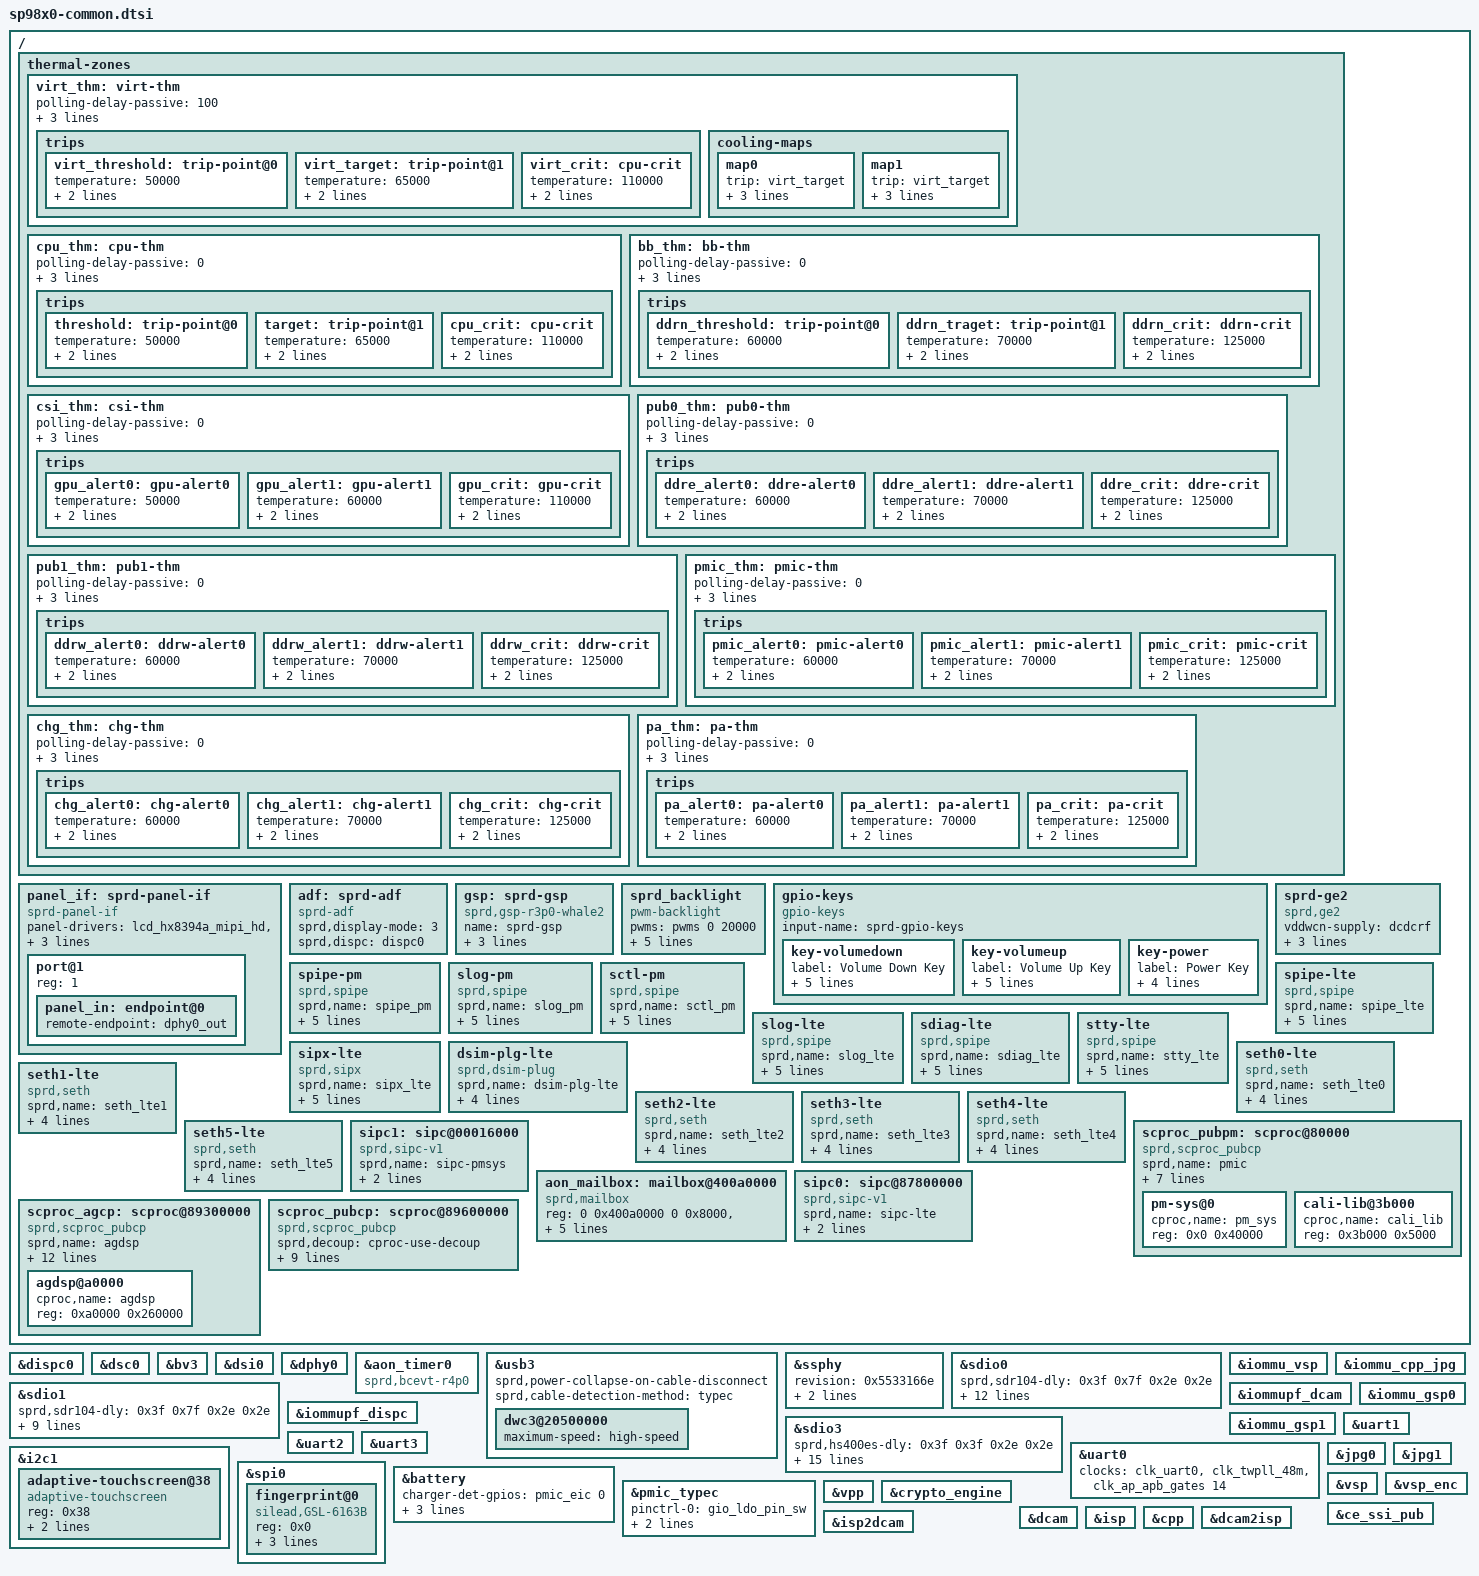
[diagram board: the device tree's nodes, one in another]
/*
 * Spreadtrum SP98x0 board common DTS file
 *
 * Copyright (C) 2016, Spreadtrum Communications Inc.
 *
 * This file is licensed under a dual GPLv2 or X11 license.
 */

#include "lcd/lcd_hx8394a_mipi_hd.dtsi"
#include "lcd/lcd_s6e3fa3_mipi_fhd.dtsi"
#include "lcd/lcd_nt35596_mipi_fhd.dtsi"
#include "lcd/lcd_nt35597_mipi_2k.dtsi"
#include "lcd/lcd_ili9885_mipi_fhd.dtsi"
#include "lcd/lcd_nt35532_mipi.dtsi"
#include "lcd/lcd_dummy_mipi.dtsi"
#include <dt-bindings/thermal/thermal.h>

/ {
	thermal-zones {

		virt_thm: virt-thm {
			polling-delay-passive = <100>;
			polling-delay = <1000>;
			sustainable-power = <2000>;

			thermal-sensors = <&virt_sensor  11>;
			trips {
				virt_threshold: trip-point@0 {
					temperature = <50000>;
					hysteresis = <1000>;
					type = "passive";
				};
				virt_target: trip-point@1 {
					temperature = <65000>;
					hysteresis = <1000>;
					type = "passive";
				};
				virt_crit: cpu-crit {
					temperature = <110000>; /* millicelsius */
					hysteresis = <2000>; /* millicelsius */
					type = "critical";
				};
			};

			cooling-maps {
				map0 {
					trip = <&virt_target>;
					contribution = <1024>;
					cooling-device =
					<&lit_cpu_cooling  THERMAL_NO_LIMIT  THERMAL_NO_LIMIT>;
				};
				map1 {
					trip = <&virt_target>;
					contribution = <761>;
					cooling-device =
					<&big_cpu_cooling  THERMAL_NO_LIMIT  THERMAL_NO_LIMIT>;
				};
			};
		};

		cpu_thm: cpu-thm {
			polling-delay-passive = <0>;
			polling-delay = <0>;
			sustainable-power = <2000>;

			thermal-sensors = <&ap_thm  0>;
			trips {
				threshold: trip-point@0 {
					temperature = <50000>;
					hysteresis = <1000>;
					type = "passive";
				};
				target: trip-point@1 {
					temperature = <65000>;
					hysteresis = <1000>;
					type = "passive";
				};
				cpu_crit: cpu-crit {
					temperature = <110000>; /* millicelsius */
					hysteresis = <2000>; /* millicelsius */
					type = "critical";
				};
			};
		};

		bb_thm: bb-thm {
			polling-delay-passive = <0>;
			polling-delay = <0>;
			sustainable-power = <2000>;
			thermal-sensors = <&ap_thm  2>;
			trips {
				ddrn_threshold: trip-point@0 {
					temperature = <60000>;
					hysteresis = <1000>;
					type = "passive";
				};
				ddrn_traget: trip-point@1 {
					temperature = <70000>;
					hysteresis = <1000>;
					type = "passive";
				};
				ddrn_crit: ddrn-crit {
					temperature = <125000>;
					hysteresis = <2000>;
					type = "critical";
				};
			};
		};

		csi_thm: csi-thm {
			polling-delay-passive = <0>;
			polling-delay = <0>;
			sustainable-power = <2000>;
			thermal-sensors = <&ap_thm  3>;
			trips {
				gpu_alert0: gpu-alert0 {
					temperature = <50000>;
					hysteresis = <1000>;
					type = "passive";
				};
				gpu_alert1: gpu-alert1 {
					temperature = <60000>;
					hysteresis = <1000>;
					type = "passive";
				};
				gpu_crit: gpu-crit {
					temperature = <110000>;
					hysteresis = <2000>;
					type = "critical";
				};
			};
		};

		pub0_thm: pub0-thm {
			polling-delay-passive = <0>;
			polling-delay = <0>;
			sustainable-power = <2000>;
			thermal-sensors = <&ap_thm  4>;
			trips {
				ddre_alert0: ddre-alert0 {
					temperature = <60000>;
					hysteresis = <1000>;
					type = "passive";
				};
				ddre_alert1: ddre-alert1 {
					temperature = <70000>;
					hysteresis = <1000>;
					type = "passive";
				};
				ddre_crit: ddre-crit {
					temperature = <125000>;
					hysteresis = <2000>;
					type = "critical";
				};
			};
		};

		pub1_thm: pub1-thm {
			polling-delay-passive = <0>;
			polling-delay = <0>;
			sustainable-power = <2000>;
			thermal-sensors = <&ap_thm  5>;
			trips {
				ddrw_alert0: ddrw-alert0 {
					temperature = <60000>;
					hysteresis = <1000>;
					type = "passive";
				};
				ddrw_alert1: ddrw-alert1 {
					temperature = <70000>;
					hysteresis = <1000>;
					type = "passive";
				};
				ddrw_crit: ddrw-crit {
					temperature = <125000>;
					hysteresis = <2000>;
					type = "critical";
				};
			};
		};

		pmic_thm: pmic-thm {
			polling-delay-passive = <0>;
			polling-delay = <0>;
			sustainable-power = <2000>;
			thermal-sensors = <&pmic_thermal 7>;
			trips {
				pmic_alert0: pmic-alert0 {
					temperature = <60000>;
					hysteresis = <1000>;
					type = "passive";
				};
				pmic_alert1: pmic-alert1 {
					temperature = <70000>;
					hysteresis = <1000>;
					type = "passive";
				};
				pmic_crit: pmic-crit {
					temperature = <125000>;
					hysteresis = <2000>;
					type = "critical";
				};
			};
		};

		chg_thm: chg-thm {
			polling-delay-passive = <0>;
			polling-delay = <0>;
			sustainable-power = <2000>;
			thermal-sensors = <&chg_temp  8>;
			trips {
				chg_alert0: chg-alert0 {
					temperature = <60000>;
					hysteresis = <1000>;
					type = "passive";
				};
				chg_alert1: chg-alert1 {
					temperature = <70000>;
					hysteresis = <1000>;
					type = "passive";
				};
				chg_crit: chg-crit {
					temperature = <125000>;
					hysteresis = <2000>;
					type = "critical";
				};
			};
		};

		pa_thm: pa-thm {
			polling-delay-passive = <0>;
			polling-delay = <0>;
			sustainable-power = <2000>;
			thermal-sensors = <&pa_temp  9>;
			trips {
				pa_alert0: pa-alert0 {
					temperature = <60000>;
					hysteresis = <1000>;
					type = "passive";
				};
				pa_alert1: pa-alert1 {
					temperature = <70000>;
					hysteresis = <1000>;
					type = "passive";
				};
				pa_crit: pa-crit {
					temperature = <125000>;
					hysteresis = <2000>;
					type = "critical";
				};
			};
		};
	};

	panel_if: sprd-panel-if {
		compatible = "sprd-panel-if";
		#address-cells = <1>;
		#size-cells = <0>;
		panel-drivers = <
			&lcd_hx8394a_mipi_hd
			&lcd_s6e3fa3_mipi_fhd
			&lcd_nt35596_mipi_fhd
			&lcd_nt35597_mipi_2k
			&lcd_ili9885_mipi_fhd
			&lcd_nt35532_mipi_fhd
			&lcd_dummy_mipi_hd
		>;

		/* input port */
		port@1 {
		/* WARNING: the reg property must be 1 ! */
			reg = <1>;
			panel_in: endpoint@0 {
				remote-endpoint = <&dphy0_out>;
			};
		};
	};

	adf: sprd-adf {
		compatible = "sprd-adf";
		status = "okay";
		sprd,display-mode = <3>;
		sprd,dispc = <&dispc0>;
	};

	gsp: sprd-gsp {
		 compatible = "sprd,gsp-r3p0-whale2";
		 name = "sprd-gsp";
		 core-cnt = <1>;
		 io-cnt = <7>;
		 cores = <&gsp_core0>;
	};

	sprd_backlight {
		compatible = "pwm-backlight";
		pwms = <&pwms 0 20000>;
		pwm-names = "backlight";
		brightness_max = <256>;
		brightness-levels=<
			                          6   6   6   6
			  6   6   6   6   6   6   6   7   8   9
			 10  11  12  13  14  15  16  17  18  19
			 20  21  22  23  24  25  26  27  28  29
			 30  31  32  33  34  35  36  37  38  39
			 40  41  42  43  44  45  46  47  48  49
			 50  51  52  53  54  55  56  57  58  59
			 60  61  62  63  64  65  66  67  68  69
			 70  71  72  73  74  75  76  77  78  79
			 80  81  82  83  84  85  86  87  88  89
			 90  91  92  93  94  95  96  97  98  99
			100 101 102 103 104 105 106 107 108 109
			110 111 112 113 114 115 116 117 118 119
			120 121 122 123 124 125 126 127 128 129
			130 131 132 133 134 135 136 137 138 139
			140 141 142 143 144 145 146 147 148 149
			150 151 152 153 154 155 156 157 158 159
			160 161 162 163 164 165 166 167 168 169
			170 171 172 173 174 175 176 177 178 179
			180 181 182 183 184 185 186 187 188 189
			190 191 192 193 194 195 196 197 198 199
			200 201 202 203 204 205 206 207 208 209
			210 211 212 213 214 215 216 217 218 219
			220 221 222 223 224 225 226 227 228 229
			230 231 232 233 234 235 236 237 238 239
			240 241 242 243 244 245 246 247 248 249
			250 251
			>;
		default-brightness-level = <25>;
	};

	gpio-keys {
		compatible = "gpio-keys";
		input-name = "sprd-gpio-keys";
		status = "okay";

		key-volumedown {
			label = "Volume Down Key";
			linux,code = <114>;
			gpios = <&ap_eic 2 1>;
			debounce-interval = <2>;
			gpio-key,wakeup;
			gpio-key,level-trigger;
		};

		key-volumeup {
			label = "Volume Up Key";
			linux,code = <115>;
			gpios = <&pmic_eic 10 0>;
			debounce-interval = <2>;
			gpio-key,wakeup;
			gpio-key,level-trigger;
		};

		key-power {
			label = "Power Key";
			linux,code = <116>;
			gpios = <&pmic_eic 1 0>;
			gpio-key,wakeup;
			gpio-key,level-trigger;
		};
	};

	sprd-ge2 {
		compatible = "sprd,ge2";
		vddwcn-supply = <&dcdcrf>;
		clock-names = "clk_32k","source","enable";
		clocks = <&clk_aux0>,<&ext_32k>,
			 <&clk_aon_apb_gates1 2>;
		chip-en-gpios = <&ap_gpio 86 0>;
	};

	spipe-pm {
		compatible = "sprd,spipe";
		sprd,name = "spipe_pm";
		sprd,dst = <6>;
		sprd,channel = <4>;
		sprd,ringnr = <4>;
		sprd,size-rxbuf = <0x100>; /* 256 */
		sprd,size-txbuf = <0x400>; /* 1024 */
	};

	slog-pm {
		compatible = "sprd,spipe";
		sprd,name = "slog_pm";
		sprd,dst = <6>;
		sprd,channel = <5>;
		sprd,ringnr = <1>;
		sprd,size-rxbuf = <0x800>; /* 2*1024*/
		sprd,size-txbuf = <0x100>; /* 256 */
	};

	sctl-pm {
		compatible = "sprd,spipe";
		sprd,name = "sctl_pm";
		sprd,dst = <6>;
		sprd,channel = <6>;
		sprd,ringnr = <1>;
		sprd,size-rxbuf = <0x100>; /* 128*/
		sprd,size-txbuf = <0x40>; /* 64 */
	};

	spipe-lte {
		compatible = "sprd,spipe";
		sprd,name = "spipe_lte";
		sprd,dst = <5>;
		sprd,channel = <4>;
		sprd,ringnr = <15>;
		sprd,size-rxbuf = <0x1000>; /* 4*1024 */
		sprd,size-txbuf = <0x1000>; /* 4*1024 */
	};

	slog-lte {
		compatible = "sprd,spipe";
		sprd,name = "slog_lte";
		sprd,dst = <5>;
		sprd,channel = <5>;
		sprd,ringnr = <1>;
		sprd,size-rxbuf = <0x40000>; /* 256*1024*/
		sprd,size-txbuf = <0x8000>; /* 32*1024 */
	};

	sdiag-lte {
		compatible = "sprd,spipe";
		sprd,name = "sdiag_lte";
		sprd,dst = <5>;
		sprd,channel = <21>;
		sprd,ringnr = <1>;
		sprd,size-rxbuf = <0x40000>; /* 256*1024*/
		sprd,size-txbuf = <0x8000>; /* 32*1024 */
	};

	stty-lte {
		compatible = "sprd,spipe";
		sprd,name = "stty_lte";
		sprd,dst = <5>;
		sprd,channel = <6>;
		sprd,ringnr = <32>;
		sprd,size-rxbuf = <0x0800>; /* 2*1024*/
		sprd,size-txbuf = <0x0800>; /* 2*1024 */
	};

	sipx-lte {
		compatible = "sprd,sipx";
		sprd,name = "sipx_lte";
		sprd,dst = <5>;
		sprd,dl-pool = <1024>;
		sprd,dl-ack-pool = <512>;
		sprd,ul-pool = <1024>;
		sprd,ul-ack-pool = <1024>;
	};

	dsim-plg-lte {
		compatible = "sprd,dsim-plug";
		sprd,name = "dsim-plg-lte";
		sprd,dst = <5>;
		sprd,channel = <23>;
		sim1-gpios = <&ap_gpio 40 0>;
		sim2-gpios = <&ap_gpio 41 0>;
	};

	seth0-lte {
		compatible = "sprd,seth";
		sprd,name = "seth_lte0";
		sprd,dst = <5>;
		sprd,channel = <7>;
		sprd,blknum = <256>;
		sprd,poolsize = <16>;
	};

	seth1-lte {
		compatible = "sprd,seth";
		sprd,name = "seth_lte1";
		sprd,dst = <5>;
		sprd,channel = <8>;
		sprd,blknum = <256>;
		sprd,poolsize = <16>;
	};

	seth2-lte {
		compatible = "sprd,seth";
		sprd,name = "seth_lte2";
		sprd,dst = <5>;
		sprd,channel = <9>;
		sprd,blknum = <256>;
		sprd,poolsize = <16>;
	};

	seth3-lte {
		compatible = "sprd,seth";
		sprd,name = "seth_lte3";
		sprd,dst = <5>;
		sprd,channel = <18>;
		sprd,blknum = <256>;
		sprd,poolsize = <16>;
	};

	seth4-lte {
		compatible = "sprd,seth";
		sprd,name = "seth_lte4";
		sprd,dst = <5>;
		sprd,channel = <19>;
		sprd,blknum = <256>;
		sprd,poolsize = <16>;
	};

	seth5-lte {
		compatible = "sprd,seth";
		sprd,name = "seth_lte5";
		sprd,dst = <5>;
		sprd,channel = <20>;
		sprd,blknum = <256>;
		sprd,poolsize = <16>;
	};

	sipc1: sipc@00016000 {
		compatible = "sprd,sipc-v1";
		sprd,name = "sipc-pmsys";
		sprd,dst = <6 1>; /* <dst core-id> */
		/* <ap-addr dst-maped-addr size> */
		sprd,smem-info = <0x00016000 0x00016000 0x2000>;
	};

	scproc_pubpm: scproc@80000 {
		compatible = "sprd,scproc_pubcp";
		sprd,name = "pmic";
		sprd,syscon-ap-apb = <&aon_apb_controller>;
		sprd,syscon-ap-pmu = <&pmu_apb_controller>;
		/* <shut_down deep_sleep core_reset sys_reset get_status> */
		sprd,ctrl-reg = <0xff 0xff 0xc4 0xc4 0xff>;
		sprd,ctrl-mask = <0x400 0x800000 0x2 0x200000 0x1>;
		sprd,ctrl-type = <0x0 0x1 0x1 0x1 0x1>;
		/* <CP_start_addr total_size> = <+128M 83M> */
		reg = <0 0x80000 0 0x40000>;
		#address-cells = <1>;
		#size-cells = <1>;
		/* segnr=1 */
		ranges = <0x0 0x0 0x80000 0x3b000>,
			<0x3b000 0x0 0xbb000 0x5000>;
		pm-sys@0 {
			cproc,name = "pm_sys";
			reg = <0x0 0x40000>; /* <pmsys_addr size> */
		};

		cali-lib@3b000 {
			cproc,name = "cali_lib";
			/* <cali_lib_start_addr size> */
			reg = <0x3b000 0x5000>;
		};
	};

	aon_mailbox: mailbox@400a0000 {
		compatible = "sprd,mailbox";
		reg = <0 0x400a0000 0 0x8000>,
		      <0 0x400a8000 0 0x8000>;
		sprd,syscon-ap-apb = <&aon_apb_controller>;
		interrupts = <GIC_SPI 28 0>,
			     <GIC_SPI 29 0>;
		sprd,core-cnt = <6>;
		sprd,version = <2>;
	};

	sipc0: sipc@87800000 {
		compatible = "sprd,sipc-v1";
		sprd,name = "sipc-lte";
		sprd,dst = <5 2>; /* <dst core-id> */
		/* <ap-addr dst-maped-addr size> */
		sprd,smem-info = <0x87800000 0x87800000 0x600000>;
	};

	scproc_agcp: scproc@89300000 {
		compatible = "sprd,scproc_pubcp";
		sprd,name = "agdsp";
		sprd,type = <0x1>;
		sprd,syscon-ap-apb = <&aon_apb_controller>;
		sprd,syscon-ap-pmu = <&pmu_apb_controller>;
		/* <sys_shut_down deep_sleep core_reset sys_reset get_status> */
		/* <iram_pw core_shut_down core_reset boot_prot> */
		/* <agdsp_ctrl0 agdsp_ctrl1 agdsp_ctrl> */
		sprd,ctrl-reg = <0x78 0xe8 0xc4 0xff 0xff>,
				<0xff 0x7c 0x148 0x78>,
				<0x140 0x144 0x14c 0xff>;
		sprd,ctrl-mask = <0x2000000 0x280000 0x10000000 0x0 0x0>,
				<0x0 0x2000000 0x2 0x9620>,
				<0x449d0040 0x1 0x1 0x0>;
		sprd,ctrl-type = <0x1 0x1 0x1 0x1 0x1>,
				<0x1 0x1 0x0 0x0>,
				<0x0 0x0 0x0 0x0>;
		/* <agdsp_start_addr total_size> = <+128M 83M> */
		reg = <0 0x89300000 0 0x300000>;
		#address-cells = <1>;
		#size-cells = <1>;
		/* segnr=1 */
		ranges = <0xa0000 0 0x893a0000 0x260000>;
		agdsp@a0000 {
			cproc,name = "agdsp";
			reg = <0xa0000 0x260000>; /* <agdsp_addr size> */
		};
	};

	scproc_pubcp: scproc@89600000 {
		compatible = "sprd,scproc_pubcp";
		sprd,decoup = "cproc-use-decoup";
		sprd,name = "cptl";
		sprd,syscon-ap-apb = <&aon_apb_controller>;
		sprd,syscon-ap-pmu = <&pmu_apb_controller>;
		/* <shut_down deep_sleep core_reset sys_reset get_status> */
		sprd,ctrl-reg = <0x84 0xe8 0x174 0xc4 0xff>;
		sprd,ctrl-mask = <0x3000000 0x180000 0x400 0x4 0x1>;
		sprd,ctrl-type = <0x1 0x1 0x0 0x1 0x1>;
		reg = <0 0xf0000 0 0x100>; /* <iram1_base size> */
		interrupts = <0 162 0x0>; /* cp1_wdg_int */
		#address-cells = <1>;
		#size-cells = <1>;
	};
};

&dispc0 {
	status = "okay";
};

&dsc0 {
	status = "okay";
};

&bv3 {
	status = "okay";
};

&dsi0 {
	status = "okay";
};

&dphy0 {
	status = "okay";
};

&aon_timer0 {
	status = "okay";
	compatible = "sprd,bcevt-r4p0";
};

&usb3 {
	status = "okay";
	sprd,power-collapse-on-cable-disconnect;
	sprd,cable-detection-method = "typec"; /* typec or gpios or none */
	dwc3@20500000 {
		maximum-speed = "high-speed"; /* super-speed, high-speed, full-speed and etc. */
	};
};

&ssphy {
	status = "okay";
	revision = <0x5533166e>; /* 0x5533286e - USB3_PHY_TSMC_28nm; 0x5533166e - USB3_PHY_TMSC_16nm */
	sprd,phy-tune1 = <0x919f9dec>;
	sprd,phy-tune2 = <0x0f0560fe>;
};

&sdio0 {
	sprd,sdr104-dly = <0x3f 0x7f 0x2e 0x2e>;
	sprd,sdr50-dly = <0x3f 0x0 0x0 0x0>;
	vmmc-supply = <&vddsdcore>;
	vqmmc-supply = <&vddsdio>;
	voltage-ranges = <3000 3000>;
	bus-width = <4>;
	sd-uhs-sdr104;
	sd-uhs-sdr50;
	sprd,name = "sdio_sd";
	no-sdio;
	no-mmc;
	pinctrl-names = "sd0_ms_0","sd0_ms_1";
	pinctrl-0 = <&vio_sd0_ms_0>;
	pinctrl-1 = <&vio_sd0_ms_1>;
	status = "okay";
};

&sdio1 {
	sprd,sdr104-dly = <0x3f 0x7f 0x2e 0x2e>;
	sprd,sdr50-dly = <0x0 0x0 0x0 0x0>;
	voltage-ranges = <2900 3200>;
	bus-width = <4>;
	sd-uhs-sdr104;
	sd-uhs-sdr50;
	sprd,name = "sdio_wifi";
	no-sd;
	no-mmc;
	keep-power-in-suspend;
	status = "okay";
};

&sdio3 {
	sprd,hs400es-dly = <0x3f 0x3f 0x2e 0x2e>;
	sprd,hs400-dly = <0x44 0x7f 0x2e 0x2e>;
	sprd,hs200-dly = <0x0 0x8c 0x8c 0x8c>;
	sprd,ddr52-dly = <0x3f 0x75 0x14 0x14>;
	vmmc-supply = <&vddemmccore>;
	voltage-ranges = <3000 3000>;
	bus-width = <8>;
	non-removable;
	cap-mmc-hw-reset;
	mmc-hs400-enhanced-strobe;
	mmc-hs400-1_8v;
	mmc-hs200-1_8v;
	mmc-ddr-1_8v;
	sprd,name = "sdio_emmc";
	no-sdio;
	no-sd;
	status = "okay";
};


&iommu_vsp {
	status = "okay";
};

&iommu_cpp_jpg {
	status = "okay";
};

&iommupf_dcam {
	status = "okay";
};

&iommupf_dispc {
	status = "okay";
};

&iommu_gsp0 {
	status = "okay";
};

&iommu_gsp1{
	status = "okay";
};

&uart0 {
	status = "okay";
	clocks = <&clk_uart0>, <&clk_twpll_48m>,
		 <&clk_ap_apb_gates 14>;
};

&uart1 {
	status = "okay";
};

&uart2 {
	status = "okay";
};

&uart3 {
	status = "okay";
};

&i2c1 {
	status = "okay";

	adaptive-touchscreen@38 {
		compatible = "adaptive-touchscreen";
		reg = <0x38>;
		gpios = <&ap_gpio 137 0
			&ap_gpio 136 0>;
		controller = "focaltech,FT5x46";
	};
};

&spi0 {
	status = "okay";

	fingerprint@0 {
		compatible = "silead,GSL-6163B";
		reg = <0x0>;
		spi-max-frequency = <5000000>;
		label = "fingerprint keys";
		gpios = <&ap_gpio 38 0
			&ap_gpio 116 0 >;
	};
};

&battery {
	charger-det-gpios = <&pmic_eic 0 0>;
	battery-det-gpios = <&pmic_eic 9 0>;
	io-channels = <&pmic_adc 1>,<&pmic_adc 10>,
			<&pmic_adc 12>,<&pmic_adc 16>;
	io-channel-names = "adc_temp","adc_vbat",
			"adc_vchg","adc_isense";
	status = "okay";
};

&pmic_typec {
	pinctrl-names = "ldo_pin_sw","ldo_ctl_md";
	pinctrl-0 = <&gio_ldo_pin_sw>;
	pinctrl-1 = <&gio_ldo_ctl_md>;
	ldo-gpios = <&ap_gpio 151 0>;
	status = "okay";
};

&jpg0 {
	status = "okay";
};

&jpg1 {
	status = "okay";
};

&vsp {
	status = "okay";
};

&vsp_enc {
	status = "okay";
};

&vpp {
	status = "okay";
};

&crypto_engine {
	status = "okay";
};

&ce_ssi_pub {
	status = "okay";
};

&dcam {
	status = "okay";
};

&isp {
	status = "okay";
};

&cpp {
	status = "okay";
};

&dcam2isp {
	status = "okay";
};

&isp2dcam {
	status = "okay";
};
